# R7FA6M4AF register map
Vendor: Renesas Electronics Corporation; Series: RA6; File version: 1.20.04
CPU: CM33 r0p4, little endian, MPU, FPU, VTOR, 4 interrupt priority bits, 96 interrupts
Registers are 8-bit, read-write, reset 0x0 unless marked. A register's access mark holds for its fields unless they carry their own. Offsets are from the block's base; [hi:lo] are bit positions; {n}, {i} and the like mark numbered series.

## TSN — Temperature Sensor
Base 0x400F3000
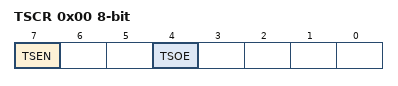
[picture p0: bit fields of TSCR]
0x00 TSCR — Temperature Sensor Control Register
  [7] TSEN — Temperature Sensor Enable
    0=Stop the temperature sensor; 1=Start the temperature sensor
  [4] TSOE — Temperature Sensor Output Enable
    0=Disable output from the temperature sensor to the ADC12; 1=Enable output from the temperature sensor to the ADC12

## CRC — Cyclic Redundancy Check Calculator
Base 0x40108000
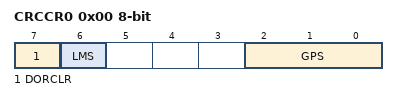
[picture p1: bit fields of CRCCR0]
0x00 CRCCR0 — CRC Control Register 0
  [7] DORCLR wo — CRCDOR/CRCDOR_HA/CRCDOR_BY Register Clear
    0=No effect; 1=Clear the CRCDOR/CRCDOR_HA/CRCDOR_BY register
  [6] LMS — CRC Calculation Switching
    0=Generate CRC code for LSB-first communication; 1=Generate CRC code for MSB-first communication
  [2:0] GPS — CRC Generating Polynomial Switching
    1=8-bit CRC-8 (X8 + X2 + X + 1); 2=16-bit CRC-16 (X16 + X15 + X2 + 1); 3=16-bit CRC-CCITT (X16 + X12 + X5 + 1); 4=32-bit CRC-32 (X32 + X26 + X23 + X22 + X16 + X12 + X11 +X10 + X8 + X7 + X5 + X4 + X2 + X + 1); 5=32-bit CRC-32C (X32 + X28 + X27 + X26 + X25 + X23 + X22 + X20 + X19 + X18 + X14 + X13 + X11 + X10 + X9 + X8 + X6 + 1); other=Others (No calculation is executed)
0x04 CRCDIR 32-bit — CRC Data Input Register
0x04 CRCDIR_BY (alternate view of CRCDIR) — CRC Data Input Register
0x08 CRCDOR 32-bit — CRC Data Output Register
0x08 CRCDOR_HA 16-bit (alternate view of CRCDOR) — CRC Data Output Register
0x08 CRCDOR_BY (alternate view of CRCDOR) — CRC Data Output Register

## DOC — Data Operation Circuit
Base 0x40109000
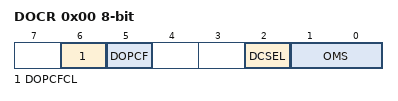
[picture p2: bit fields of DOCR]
0x00 DOCR — DOC Control Register
  [6] DOPCFCL — DOPCF Clear
    0=Retain DOPCF flag state; 1=Clear DOPCF flag
  [5] DOPCF ro — DOC Flag
  [2] DCSEL — Detection Condition Select
    0=Set DOPCF flag when data mismatch is detected; 1=Set DOPCF flag when data match is detected
  [1:0] OMS — Operating Mode Select
    0=Data comparison mode; 1=Data addition mode; 2=Data subtraction mode; 3=Setting prohibited
0x02 DODIR 16-bit — DOC Data Input Register
0x04 DODSR 16-bit — DOC Data Setting Register

## GPT_OPS — Output Phase Switching Controller
Base 0x40169A00
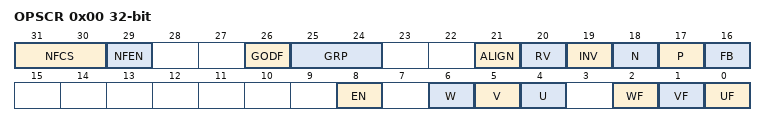
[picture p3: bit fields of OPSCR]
0x00 OPSCR 32-bit — Output Phase Switching Control Register
  [31:30] NFCS — External Input Noise Filter Clock Selection
    0=PCLKD/1; 1=PCLKD/4; 2=PCLKD/16; 3=PCLKD/64
  [29] NFEN — External Input Noise Filter Enable
    0=Do not use a noise filter on the external input; 1=Use a noise filter on the external input
  [26] GODF — Group Output Disable Function
    0=This bit function is ignored; 1=Group disable clears the OPSCR.EN bit
  [25:24] GRP — Output Disabled Source Selection
  [21] ALIGN — Input Phase Alignment
    0=Input phase aligned to PCLKD; 1=Input phase aligned to the falling edge of PWM
  [20] RV — Output Phase Rotation Direction Reversal Control
    0=Positive rotation; 1=Reverse rotation
  [19] INV — Output Phase Invert Control
    0=Positive logic (active-high) output; 1=Negative logic (active-low) output
  [18] N — Negative-Phase Output (N) Control
    0=Level signal output; 1=PWM signal output
  [17] P — Positive-Phase Output (P) Control
    0=Level signal output; 1=PWM signal output
  [16] FB — External Feedback Signal Enable
    0=Select the external input; 1=Select the soft setting (OPSCR.UF, VF, WF)
  [8] EN — Output Phase Enable
    0=Do not output (Hi-Z external pin); 1=Output
  [6] W ro — Input W-Phase Monitor
  [5] V ro — Input V-Phase Monitor
  [4] U ro — Input U-Phase Monitor
  [2] WF
  [1] VF
  [0] UF

## DAC12 — 12-bit D/A converter
Base 0x40171000
{0x0+2i} DADR{i} (i=0..1) 16-bit — D/A Data Register {i}
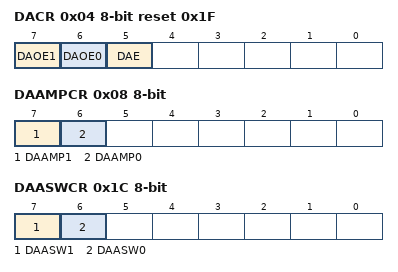
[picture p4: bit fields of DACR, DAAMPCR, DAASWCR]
0x04 DACR reset 0x1F — D/A Control Register
  [7] DAOE1 — D/A Output Enable 1
    0=Disable analog output of channel 1 (DA1); 1=Enable D/A conversion of channel 1 (DA1)
  [6] DAOE0 — D/A Output Enable 0
    0=Disable analog output of channel 0 (DA0); 1=Enable D/A conversion of channel 0 (DA0)
  [5] DAE — D/A Enable
    0=Control D/A conversion of channels 0 and 1 individually; 1=Control D/A conversion of channels 0 and 1 collectively
0x05 DADPR — DADRn Format Select Register
  [7] DPSEL — DADRn Format Select
    0=Right-justified format; 1=Left-justified format
0x06 DAADSCR — D/A A/D Synchronous Start Control Register
  [7] DAADST — D/A A/D Synchronous Conversion
    0=Do not synchronize DAC12 with ADC12 (unit 1) operation (disable interference reduction between D/A and A/D conversion); 1=Synchronize DAC12 with ADC12 (unit 1) operation (enable interference reduction between D/A and A/D conversion)
0x08 DAAMPCR — D/A Output Amplifier Control Register
  [7] DAAMP1 — Amplifier Control 1
    0=Do not use channel 1 output amplifier; 1=Use channel 1 output amplifier
  [6] DAAMP0 — Amplifier Control 0
    0=Do not use channel 0 output amplifier; 1=Use channel 0 output amplifier
0x1C DAASWCR — D/A Amplifier Stabilization Wait Control Register
  [7] DAASW1 — D/A Amplifier Stabilization Wait 1
    0=Amplifier stabilization wait off (output) for channel 1; 1=Amplifier stabilization wait on (high-Z) for channel 1
  [6] DAASW0 — D/A Amplifier Stabilization Wait 0
    0=Amplifier stabilization wait off (output) for channel 0; 1=Amplifier stabilization wait on (high-Z) for channel 0
0x10C0 DAADUSR — D/A A/D Synchronous Unit Select Register
  [1] AMADSEL1 — A/D Unit 1 Select
    0=Do not select unit 1; 1=Select unit 1

## TSD — Temperature Sensor Calibration Data
Base 0x407FB000
0x17C TSCDR 32-bit ro (reset mask 0xFFFF0000) — Temperature Sensor Calibration Data Register
  [15:0] TSCDR — Temperature Sensor Calibration Data

## FLAD — Data Flash
Base 0x407FC000
0x40 FCKMHZ reset 0x3C — Data Flash Access Frequency Register
